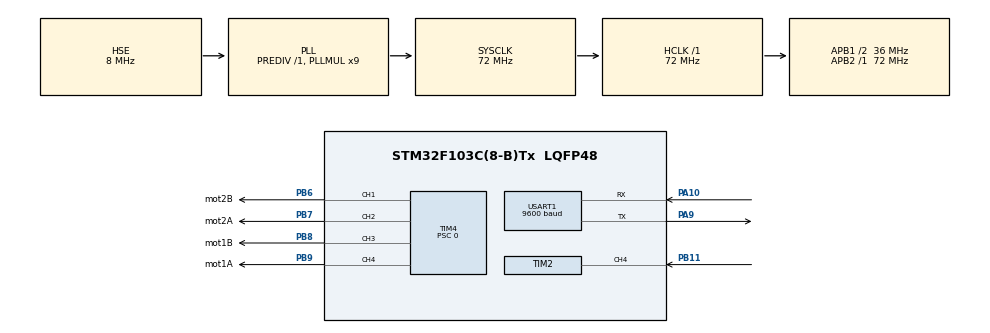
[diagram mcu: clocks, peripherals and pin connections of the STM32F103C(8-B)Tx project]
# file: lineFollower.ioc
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Mcu.Family=STM32F1
Mcu.Name=STM32F103C(8-B)Tx
Mcu.Package=LQFP48
NVIC.PriorityGroup=NVIC_PRIORITYGROUP_4
NVIC.TIM2_IRQn=true\:0\:0\:false\:false\:true\:true\:true
PA10.Mode=Asynchronous
PA10.Signal=USART1_RX
PA9.Mode=Asynchronous
PA9.Signal=USART1_TX
PB11.Signal=S_TIM2_CH4
PB6.GPIO_Label=mot2B
PB6.Signal=S_TIM4_CH1
PB7.GPIO_Label=mot2A
PB7.Signal=S_TIM4_CH2
PB8.GPIO_Label=mot1B
PB8.Signal=S_TIM4_CH3
PB9.GPIO_Label=mot1A
PB9.Signal=S_TIM4_CH4
PD0-OSC_IN.Mode=HSE-External-Oscillator
PD0-OSC_IN.Signal=RCC_OSC_IN
PD1-OSC_OUT.Mode=HSE-External-Oscillator
PD1-OSC_OUT.Signal=RCC_OSC_OUT
ProjectManager.HeapSize=0x200
ProjectManager.StackSize=0x400
ProjectManager.TargetToolchain=STM32CubeIDE
RCC.AHBFreq_Value=72000000
RCC.APB1CLKDivider=RCC_HCLK_DIV2
RCC.APB1Freq_Value=36000000
RCC.APB1TimFreq_Value=72000000
RCC.APB2Freq_Value=72000000
RCC.APB2TimFreq_Value=72000000
RCC.HCLKFreq_Value=72000000
RCC.PLLMUL=RCC_PLL_MUL9
RCC.PLLSourceVirtual=RCC_PLLSOURCE_HSE
RCC.SYSCLKFreq_VALUE=72000000
RCC.SYSCLKSource=RCC_SYSCLKSOURCE_PLLCLK
RCC.USBFreq_Value=72000000
SH.S_TIM2_CH4.0=TIM2_CH4,Input_Capture4_from_TI4
SH.S_TIM4_CH1.0=TIM4_CH1,PWM Generation1 CH1
SH.S_TIM4_CH2.0=TIM4_CH2,PWM Generation2 CH2
SH.S_TIM4_CH3.0=TIM4_CH3,PWM Generation3 CH3
SH.S_TIM4_CH4.0=TIM4_CH4,PWM Generation4 CH4
TIM2.Channel-Input_Capture4_from_TI4=TIM_CHANNEL_4
TIM2.Period=0xffff-1
TIM2.Prescaler=72-1
TIM4.AutoReloadPreload=TIM_AUTORELOAD_PRELOAD_ENABLE
TIM4.Channel-PWM\ Generation1\ CH1=TIM_CHANNEL_1
TIM4.Channel-PWM\ Generation2\ CH2=TIM_CHANNEL_2
TIM4.Channel-PWM\ Generation3\ CH3=TIM_CHANNEL_3
TIM4.Channel-PWM\ Generation4\ CH4=TIM_CHANNEL_4
TIM4.Prescaler=0
USART1.BaudRate=9600
USART1.VirtualMode=VM_ASYNC
VP_SYS_VS_ND.Mode=No_Debug
VP_TIM2_VS_ClockSourceINT.Mode=Internal
VP_TIM4_VS_ClockSourceINT.Mode=Internal
board=custom

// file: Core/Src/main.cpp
/* USER CODE BEGIN Header */
/**
 ******************************************************************************
 * @file           : main.c
 * @brief          : Main program body
 ******************************************************************************
 * @attention
 *
 * <h2><center>&copy; Copyright (c) 2021 STMicroelectronics.
 * All rights reserved.</center></h2>
 *
 * This software component is licensed by ST under BSD 3-Clause license,
 * the "License"; You may not use this file except in compliance with the
 * License. You may obtain a copy of the License at:
 *                        opensource.org/licenses/BSD-3-Clause
 *
 ******************************************************************************
 */
/* USER CODE END Header */
#include "main.h"
#include "sensors.h"
#include "stm_delay.h"
#include <stdio.h>
#include <string.h>
#include <map>

TIM_HandleTypeDef htim2;
TIM_HandleTypeDef htim4;
UART_HandleTypeDef huart1;
uint32_t distance = 0;

void SystemClock_Config(void);
static void MX_GPIO_Init(void);
static void MX_TIM4_Init(void);
static void MX_TIM2_Init(void);
static void MX_USART1_UART_Init(void);
void data_to_pid(char[]);
void read_hc05();
/* USER CODE BEGIN PFP */
IRpins lineSensorS = { { GPIOA, GPIO_PIN_8 }, { GPIOA, GPIO_PIN_12 }, { GPIOB,
GPIO_PIN_12 }, { GPIOB, GPIO_PIN_14 } };

Motor motorA(TIM_CHANNEL_2, TIM_CHANNEL_1, &htim4);
Motor motorB(TIM_CHANNEL_4, TIM_CHANNEL_3, &htim4);
CarIR lilRobot (&motorA, &motorB, lineSensorS);
STMPIN echo = { GPIOB, GPIO_PIN_11 };
STMPIN trig = { GPIOB, GPIO_PIN_10 };
/* USER CODE END PFP */

int main(void) {

	/* MCU Configuration--------------------------------------------------------*/

	/* Reset of all peripherals, Initializes the Flash interface and the Systick.
	 */
	HAL_Init();

	/* Configure the system clock */
	SystemClock_Config();

	/* Initialize all configured peripherals */
	MX_GPIO_Init();
	MX_TIM4_Init();
	MX_TIM2_Init();
	MX_USART1_UART_Init();
	/* USER CODE BEGIN 2 */
	HAL_TIM_PWM_Start(&htim4,TIM_CHANNEL_4);
	HAL_TIM_PWM_Start(&htim4,TIM_CHANNEL_3);
	HAL_TIM_PWM_Start(&htim4,TIM_CHANNEL_2);
	HAL_TIM_PWM_Start(&htim4,TIM_CHANNEL_1);
	HAL_TIM_OC_Start_IT(&htim2, TIM_CHANNEL_4);
	/* USER CODE END 2 */
	if (DWT_Delay_Init()) {
		Error_Handler();
	}
	/* USER CODE BEGIN WHILE */
	uart_println(&huart1, (char*) "START");
	HAL_Delay(5000);
	while (1) {
		get_distance();
		read_hc05();
		char buffer[100];
		sprintf(buffer, "Distance:%d", int(distance));
		uart_println(&huart1, buffer);
		lilRobot.run();
		if (distance> 0 &&  distance < 20 ) {
			lilRobot.comeback();
		 }
	}
	/* USER CODE END 3 */
}
void read_hc05(){
	char buffer[100]={0};
	HAL_UART_Receive(&huart1,(uint8_t*) buffer, 100, 4000);
	if (buffer[0] != '\0'){
		uart_println(&huart1, (char*)"Data received:");
		uart_println(&huart1, buffer);
		uart_println(&huart1, (char*)"");
		data_to_pid(buffer);
		memset(buffer, 0, 100);
		sprintf(buffer,"p:%.2f, i:%.2f, d:%.2f",lilRobot.Kp,lilRobot.Ki,lilRobot.Kd);
		uart_println(&huart1, buffer);
	}
}
void data_to_pid(char data[]){
	std::map<char,float*> pidVars={{'p',&lilRobot.Kp},{'i',&lilRobot.Ki},{'d',&lilRobot.Kd}};
	auto dataLen = strlen(data);
	for(unsigned int i=0;i<dataLen;i++){
	char c = data[i];
	if ( pidVars.find(c) != pidVars.end() ) {
		uart_println(&huart1, (char*)"Find:"+c);
		char value[10];
		int addr =0;
		for(unsigned int j=i+2;j<dataLen;j++ ){
			char n = data[j];
			if(isalnum(n)){
				value[addr]=n;
				addr++;
			}
			else{
				float valueF = atoff(value);
				*(pidVars.find(c)->second)= valueF;
				break;
			}
		}
	}
	}
}
void timer2_handler(TIM_HandleTypeDef *htim) {
	uint32_t IC_Val1 = 0;
	uint32_t IC_Val2 = 0;
	uint32_t Difference = 0;
	IC_Val1 = HAL_TIM_ReadCapturedValue(htim,
	TIM_CHANNEL_4);  // read the first value
	while (HAL_GPIO_ReadPin(echo.port, echo.pin))
		;
	IC_Val2 = __HAL_TIM_GET_COUNTER(htim);  // read second value
	__HAL_TIM_SET_COUNTER(htim, 0);
	if (IC_Val2 > IC_Val1) {
		Difference = IC_Val2 - IC_Val1;
	} else if (IC_Val1 > IC_Val2) {
		Difference = (0xffff - IC_Val1) + IC_Val2;
	}
	distance = Difference * .034 / 2;
}
int get_distance() {
	HAL_GPIO_WritePin(trig.port, trig.pin, GPIO_PIN_SET); // pull the TRIG pin HIGH
	DWT_Delay_us(10);                 // wait for 10 us
	HAL_GPIO_WritePin(trig.port, trig.pin, GPIO_PIN_RESET); // pull the TRIG pin low
	return distance;
}
/** ***@brief
 * *@retval None
 */
void SystemClock_Config(void) {
	RCC_OscInitTypeDef RCC_OscInitStruct = { 0 };
	RCC_ClkInitTypeDef RCC_ClkInitStruct = { 0 };

	/** Initializes the RCC Oscillators according to the specified parameters
	 * in the RCC_OscInitTypeDef structure.
	 */
	RCC_OscInitStruct.OscillatorType = RCC_OSCILLATORTYPE_HSE;
	RCC_OscInitStruct.HSEState = RCC_HSE_ON;
	RCC_OscInitStruct.HSEPredivValue = RCC_HSE_PREDIV_DIV1;
	RCC_OscInitStruct.HSIState = RCC_HSI_ON;
	RCC_OscInitStruct.PLL.PLLState = RCC_PLL_ON;
	RCC_OscInitStruct.PLL.PLLSource = RCC_PLLSOURCE_HSE;
	RCC_OscInitStruct.PLL.PLLMUL = RCC_PLL_MUL9;
	if (HAL_RCC_OscConfig(&RCC_OscInitStruct) != HAL_OK) {
		Error_Handler();
	}
	/** Initializes the CPU, AHB and APB buses clocks
	 */
	RCC_ClkInitStruct.ClockType = RCC_CLOCKTYPE_HCLK | RCC_CLOCKTYPE_SYSCLK |
	RCC_CLOCKTYPE_PCLK1 | RCC_CLOCKTYPE_PCLK2;
	RCC_ClkInitStruct.SYSCLKSource = RCC_SYSCLKSOURCE_PLLCLK;
	RCC_ClkInitStruct.AHBCLKDivider = RCC_SYSCLK_DIV1;
	RCC_ClkInitStruct.APB1CLKDivider = RCC_HCLK_DIV2;
	RCC_ClkInitStruct.APB2CLKDivider = RCC_HCLK_DIV1;

	if (HAL_RCC_ClockConfig(&RCC_ClkInitStruct, FLASH_LATENCY_2) != HAL_OK) {
		Error_Handler();
	}
}

static void init_ir_pins() {
	for (int i = 0; i < 4; i++) {
		STMPIN ir = lineSensorS.pinArray[i];
		GPIO_InitTypeDef GPIO_InitStruct = { 0 };
		GPIO_InitStruct.Pin = ir.pin;
		GPIO_InitStruct.Mode = GPIO_MODE_INPUT;
		GPIO_InitStruct.Pull = GPIO_NOPULL;
		GPIO_InitStruct.Speed = GPIO_SPEED_FREQ_LOW;
		HAL_GPIO_Init(ir.port, &GPIO_InitStruct);
	}
}
static void MX_GPIO_Init(void) {
	init_ir_pins();
	GPIO_InitTypeDef GPIO_InitStruct = { 0 };
	GPIO_InitStruct.Pin = trig.pin;
	GPIO_InitStruct.Mode = GPIO_MODE_OUTPUT_PP;
	GPIO_InitStruct.Speed = GPIO_SPEED_FREQ_LOW;
	GPIO_InitStruct.Pull = GPIO_NOPULL;

	HAL_GPIO_Init(trig.port, &GPIO_InitStruct);

	/* GPIO Ports Clock Enable */
	__HAL_RCC_GPIOD_CLK_ENABLE();
	__HAL_RCC_GPIOC_CLK_ENABLE();
	__HAL_RCC_GPIOB_CLK_ENABLE();
	__HAL_RCC_GPIOA_CLK_ENABLE();
}
static void MX_TIM2_Init(void) {

	TIM_ClockConfigTypeDef sClockSourceConfig = { 0 };
	TIM_MasterConfigTypeDef sMasterConfig = { 0 };
	TIM_IC_InitTypeDef sConfigIC = { 0 };

	htim2.Instance = TIM2;
	htim2.Init.Prescaler = 72 - 1;
	htim2.Init.CounterMode = TIM_COUNTERMODE_UP;
	htim2.Init.Period = 0xffff - 1;
	htim2.Init.ClockDivision = TIM_CLOCKDIVISION_DIV1;
	htim2.Init.AutoReloadPreload = TIM_AUTORELOAD_PRELOAD_DISABLE;
	if (HAL_TIM_Base_Init(&htim2) != HAL_OK) {
		Error_Handler();
	}
	sClockSourceConfig.ClockSource = TIM_CLOCKSOURCE_INTERNAL;
	if (HAL_TIM_ConfigClockSource(&htim2, &sClockSourceConfig) != HAL_OK) {
		Error_Handler();
	}
	if (HAL_TIM_IC_Init(&htim2) != HAL_OK) {
		Error_Handler();
	}
	sMasterConfig.MasterOutputTrigger = TIM_TRGO_RESET;
	sMasterConfig.MasterSlaveMode = TIM_MASTERSLAVEMODE_DISABLE;
	if (HAL_TIMEx_MasterConfigSynchronization(&htim2, &sMasterConfig)
			!= HAL_OK) {
		Error_Handler();
	}
	sConfigIC.ICPolarity = TIM_INPUTCHANNELPOLARITY_RISING;
	sConfigIC.ICSelection = TIM_ICSELECTION_DIRECTTI;
	sConfigIC.ICPrescaler = TIM_ICPSC_DIV1;
	sConfigIC.ICFilter = 0;
	if (HAL_TIM_IC_ConfigChannel(&htim2, &sConfigIC, TIM_CHANNEL_4) != HAL_OK) {
		Error_Handler();
	}
}
static void MX_TIM4_Init(void) {

	TIM_ClockConfigTypeDef sClockSourceConfig = { 0 };
	TIM_MasterConfigTypeDef sMasterConfig = { 0 };
	TIM_OC_InitTypeDef sConfigOC = { 0 };

	htim4.Instance = TIM4;
	htim4.Init.Prescaler = 1080 - 1;
	htim4.Init.CounterMode = TIM_COUNTERMODE_UP;
	htim4.Init.Period = 2000 - 1;
	htim4.Init.ClockDivision = TIM_CLOCKDIVISION_DIV1;
	htim4.Init.AutoReloadPreload = TIM_AUTORELOAD_PRELOAD_ENABLE;
	if (HAL_TIM_Base_Init(&htim4) != HAL_OK) {
		Error_Handler();
	}
	sClockSourceConfig.ClockSource = TIM_CLOCKSOURCE_INTERNAL;
	if (HAL_TIM_ConfigClockSource(&htim4, &sClockSourceConfig) != HAL_OK) {
		Error_Handler();
	}
	if (HAL_TIM_PWM_Init(&htim4) != HAL_OK) {
		Error_Handler();
	}
	sMasterConfig.MasterOutputTrigger = TIM_TRGO_RESET;
	sMasterConfig.MasterSlaveMode = TIM_MASTERSLAVEMODE_DISABLE;
	if (HAL_TIMEx_MasterConfigSynchronization(&htim4, &sMasterConfig)
			!= HAL_OK) {
		Error_Handler();
	}
	sConfigOC.OCMode = TIM_OCMODE_PWM1;
	sConfigOC.Pulse = 0;
	sConfigOC.OCPolarity = TIM_OCPOLARITY_HIGH;
	sConfigOC.OCFastMode = TIM_OCFAST_DISABLE;
	if (HAL_TIM_PWM_ConfigChannel(&htim4, &sConfigOC, TIM_CHANNEL_1)
			!= HAL_OK) {
		Error_Handler();
	}
	if (HAL_TIM_PWM_ConfigChannel(&htim4, &sConfigOC, TIM_CHANNEL_2)
			!= HAL_OK) {
		Error_Handler();
	}
	if (HAL_TIM_PWM_ConfigChannel(&htim4, &sConfigOC, TIM_CHANNEL_3)
			!= HAL_OK) {
		Error_Handler();
	}
	if (HAL_TIM_PWM_ConfigChannel(&htim4, &sConfigOC, TIM_CHANNEL_4)
			!= HAL_OK) {
		Error_Handler();
	}
	HAL_TIM_MspPostInit(&htim4);

} /* USER CODE BEGIN 4 */
static void MX_USART1_UART_Init(void) {

	huart1.Instance = USART1;
	huart1.Init.BaudRate = 9600;
	huart1.Init.WordLength = UART_WORDLENGTH_8B;
	huart1.Init.StopBits = UART_STOPBITS_1;
	huart1.Init.Parity = UART_PARITY_NONE;
	huart1.Init.Mode = UART_MODE_TX_RX;
	huart1.Init.HwFlowCtl = UART_HWCONTROL_NONE;
	huart1.Init.OverSampling = UART_OVERSAMPLING_16;
	if (HAL_UART_Init(&huart1) != HAL_OK) {
		Error_Handler();
	}
}
/* USER CODE END 4 */

void Error_Handler(void) {
	__disable_irq();
	while (1) {
	}
}

#ifdef USE_FULL_ASSERT
/**
 * @brief  Reports the name of the source file and the source line number
 *         where the assert_param error has occurred.
 * @param  file: pointer to the source file name
 * @param  line: assert_param error line source number
 * @retval None
 */
void assert_failed(uint8_t *file, uint32_t line) {
  /* USER CODE BEGIN 6 */
  /* User can add his own implementation to report the file name and line
     number,
     ex: printf("Wrong parameters value: file %s on line %d\r\n", file, line) */
  /* USER CODE END 6 */
}
#endif /* USE_FULL_ASSERT */

/************************ (C) COPYRIGHT STMicroelectronics *****END OF FILE****/
